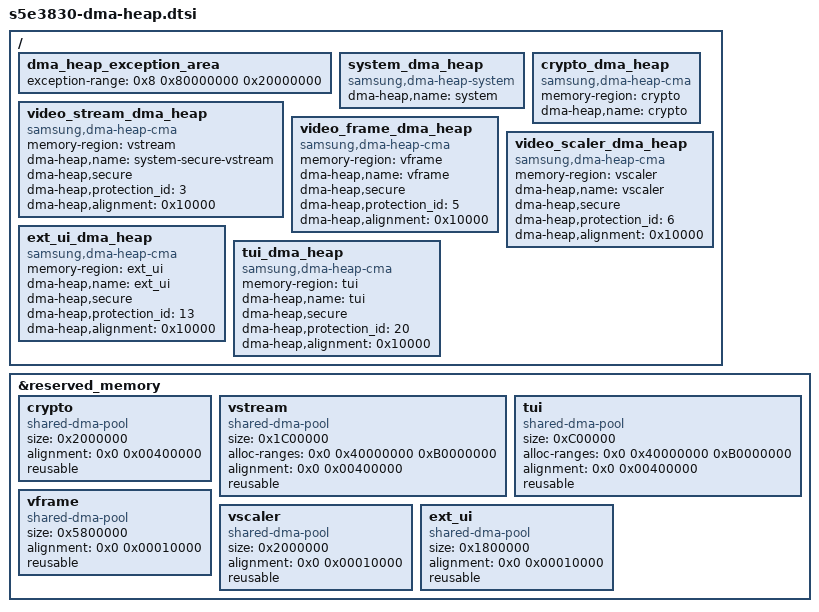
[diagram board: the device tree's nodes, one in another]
// SPDX-License-Identifier: GPL-2.0
/*
 * EXYNOS DMA HEAP device tree source for reserved-memory
 *
 * Copyright (c) 2022 Samsung Electronics Co., Ltd.
 */

/ {
	dma_heap_exception_area {
		#address-cells = <2>;
		#size-cells = <1>;
		ranges;
		exception-range = <0x8 0x80000000 0x20000000>;
	};

	system_dma_heap {
		compatible = "samsung,dma-heap-system";
		dma-heap,name = "system";
	};

	crypto_dma_heap {
		compatible = "samsung,dma-heap-cma";
		memory-region = <&crypto>;
		dma-heap,name = "crypto";
	};

	video_stream_dma_heap {
		compatible = "samsung,dma-heap-cma";
		memory-region = <&vstream>;
		dma-heap,name = "system-secure-vstream";
		dma-heap,secure;
		dma-heap,protection_id = <3>;
		dma-heap,alignment = <0x10000>;
	};

	video_frame_dma_heap {
		compatible = "samsung,dma-heap-cma";
		memory-region = <&vframe>;
		dma-heap,name = "vframe";
		dma-heap,secure;
		dma-heap,protection_id = <5>;
		dma-heap,alignment = <0x10000>;
	};

	video_scaler_dma_heap {
		compatible = "samsung,dma-heap-cma";
		memory-region = <&vscaler>;
		dma-heap,name = "vscaler";
		dma-heap,secure;
		dma-heap,protection_id = <6>;
		dma-heap,alignment = <0x10000>;
	};

	ext_ui_dma_heap {
		compatible = "samsung,dma-heap-cma";
		memory-region = <&ext_ui>;
		dma-heap,name = "ext_ui";
		dma-heap,secure;
		dma-heap,protection_id = <13>;
		dma-heap,alignment = <0x10000>;
	};

	tui_dma_heap {
		compatible = "samsung,dma-heap-cma";
		memory-region = <&tui>;
		dma-heap,name = "tui";
		dma-heap,secure;
		dma-heap,protection_id = <20>;
		dma-heap,alignment = <0x10000>;
	};
};

&reserved_memory {
	#address-cells = <2>;
	#size-cells = <1>;

	crypto: crypto {
		compatible = "shared-dma-pool";
		size = <0x2000000>;
		alignment = <0x0 0x00400000>;
		reusable;
	};

	vstream: vstream {
		compatible = "shared-dma-pool";
		size = <0x1C00000>;
		alloc-ranges = <0x0 0x40000000 0xB0000000>;
		alignment = <0x0 0x00400000>;
		reusable;
	};

	tui: tui {
		compatible = "shared-dma-pool";
		size = <0xC00000>;
		alloc-ranges = <0x0 0x40000000 0xB0000000>;
		alignment = <0x0 0x00400000>;
		reusable;
	};

	vframe: vframe {
		compatible = "shared-dma-pool";
		size = <0x5800000>; /* 800M, UHD VP9: ALIGN(12,442,112 x 50 + 4.34MB, 4MB) */
		alignment = <0x0 0x00010000>;
		reusable;
	};

	vscaler: vscaler {
		compatible = "shared-dma-pool";
		size = <0x2000000>;
		alignment = <0x0 0x00010000>;
		reusable;
	};

	ext_ui: ext_ui {
		compatible = "shared-dma-pool";
		size = <0x1800000>;
		alignment = <0x0 0x00010000>;
		reusable;
	};
};
